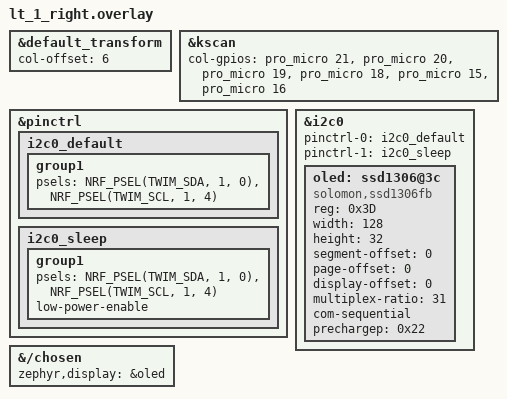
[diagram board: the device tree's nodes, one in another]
// This file was generated from a template. Edit it to match your keyboard.
// See https://zmk.dev/docs/development/hardware-integration/new-shield for more
// instructions.

#include "lt_1.dtsi"
#include <dt-bindings/pinctrl/nrf-pinctrl.h>

&default_transform {
    // Set this to the number of columns on the left side.
    col-offset = <6>;
};

&kscan {
    // Replace these comments with the GPIO pins in the matrix for the right side.
    // See https://zmk.dev/docs/development/hardware-integration/new-shield#shield-overlays
    col-gpios
        = <&pro_micro 21 GPIO_ACTIVE_HIGH>
        , <&pro_micro 20 GPIO_ACTIVE_HIGH>
        , <&pro_micro 19 GPIO_ACTIVE_HIGH>
        , <&pro_micro 18 GPIO_ACTIVE_HIGH>
        , <&pro_micro 15 GPIO_ACTIVE_HIGH>
        , <&pro_micro 16 GPIO_ACTIVE_HIGH>
        ;
};

&pinctrl {
    i2c0_default: i2c0_default {
        group1 {
            psels = <NRF_PSEL(TWIM_SDA, 1, 0)>,  /* pro_micro pin D6 = P1.00 */
                    <NRF_PSEL(TWIM_SCL, 1, 4)>;   /* pro_micro pin D8 = P1.04 */
        };
    };

    i2c0_sleep: i2c0_sleep {
        group1 {
            psels = <NRF_PSEL(TWIM_SDA, 1, 0)>,
                    <NRF_PSEL(TWIM_SCL, 1, 4)>;
            low-power-enable;
        };
    };
};

&i2c0 {
    status = "okay";
    pinctrl-0 = <&i2c0_default>;
    pinctrl-1 = <&i2c0_sleep>;
    pinctrl-names = "default", "sleep";

    oled: ssd1306@3c {
        compatible = "solomon,ssd1306fb";
        reg = <0x3D>;
        width = <128>;
        height = <32>;
        segment-offset = <0>;
        page-offset = <0>;
        display-offset = <0>;
        multiplex-ratio = <31>;
        com-sequential;
        prechargep = <0x22>;
    };
};

&oled {
    status = "okay";
};

&{/chosen} {
    zephyr,display = &oled;
};
